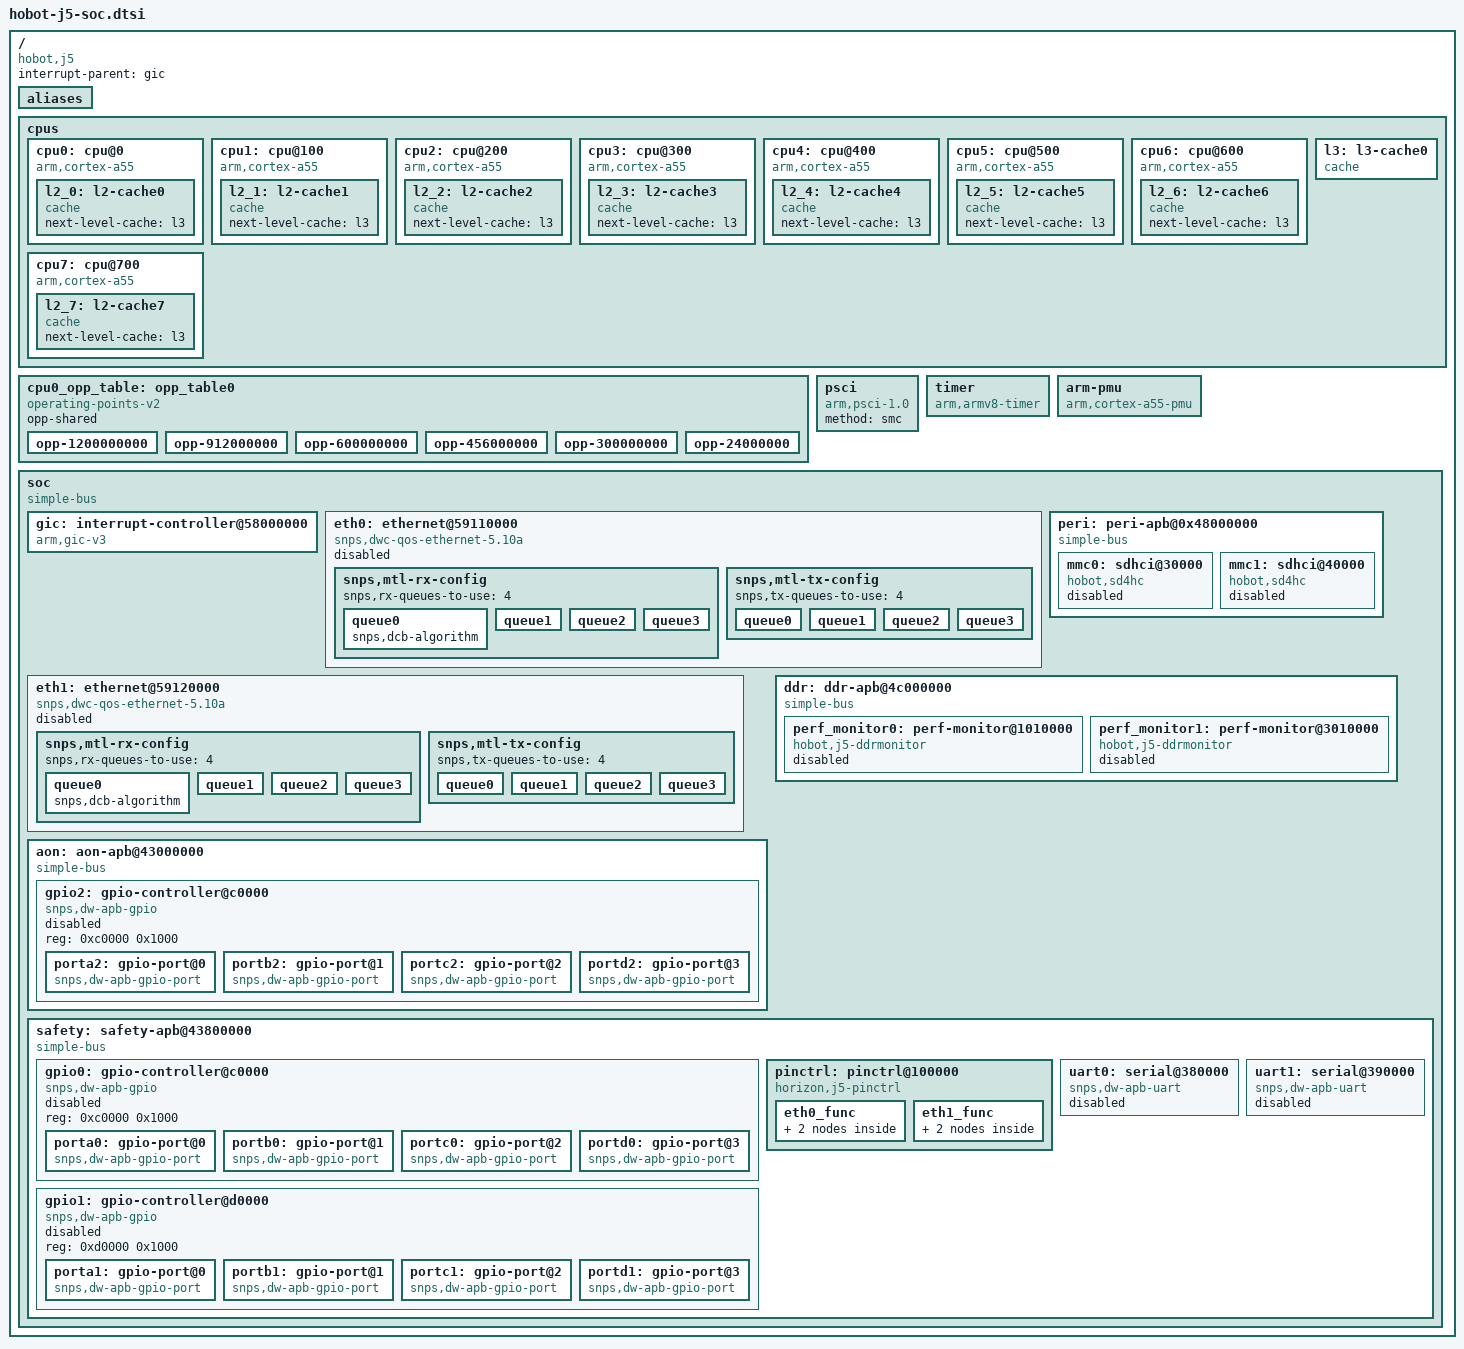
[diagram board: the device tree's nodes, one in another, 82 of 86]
// SPDX-License-Identifier: (GPL-2.0+ OR MIT)
/*
 * Copyright (c) 2021 Beijing Horizon Robotics Co., Ltd
 */

#include <dt-bindings/interrupt-controller/arm-gic.h>
#include <dt-bindings/interrupt-controller/irq.h>
/ {
	compatible = "hobot,j5";

	interrupt-parent = <&gic>;
	#address-cells = <2>;
	#size-cells = <2>;

	aliases {
		serial0 = &uart0;
		serial1 = &uart1;
		mmc0 = &mmc0;
		mmc1 = &mmc1;
	};

	cpus {
		#address-cells = <2>;
		#size-cells = <0>;

		cpu0: cpu@0 {
			device_type = "cpu";
			compatible = "arm,cortex-a55";
			reg = <0x0 0x0>;
			enable-method = "psci";
			next-level-cache = <&l2_0>;
			operating-points-v2 = <&cpu0_opp_table>;

			l2_0: l2-cache0 {
				compatible = "cache";
				next-level-cache = <&l3>;
			};
		};

		cpu1: cpu@100 {
			device_type = "cpu";
			compatible = "arm,cortex-a55";
			reg = <0x0 0x100>;
			enable-method = "psci";
			next-level-cache = <&l2_1>;
			operating-points-v2 = <&cpu0_opp_table>;

			l2_1: l2-cache1 {
				compatible = "cache";
				next-level-cache = <&l3>;
			};
		};

		cpu2: cpu@200 {
			device_type = "cpu";
			compatible = "arm,cortex-a55";
			reg = <0x0 0x200>;
			enable-method = "psci";
			next-level-cache = <&l2_2>;
			operating-points-v2 = <&cpu0_opp_table>;

			l2_2: l2-cache2 {
				compatible = "cache";
				next-level-cache = <&l3>;
			};
		};

		cpu3: cpu@300 {
			device_type = "cpu";
			compatible = "arm,cortex-a55";
			reg = <0x0 0x300>;
			enable-method = "psci";
			next-level-cache = <&l2_3>;
			operating-points-v2 = <&cpu0_opp_table>;

			l2_3: l2-cache3 {
				compatible = "cache";
				next-level-cache = <&l3>;
			};
		};

		cpu4: cpu@400 {
			device_type = "cpu";
			compatible = "arm,cortex-a55";
			reg = <0x0 0x400>;
			enable-method = "psci";
			next-level-cache = <&l2_4>;
			operating-points-v2 = <&cpu0_opp_table>;

			l2_4: l2-cache4 {
				compatible = "cache";
				next-level-cache = <&l3>;
			};
		};

		cpu5: cpu@500 {
			device_type = "cpu";
			compatible = "arm,cortex-a55";
			reg = <0x0 0x500>;
			enable-method = "psci";
			next-level-cache = <&l2_5>;
			operating-points-v2 = <&cpu0_opp_table>;

			l2_5: l2-cache5 {
				compatible = "cache";
				next-level-cache = <&l3>;
			};
		};

		cpu6: cpu@600 {
			device_type = "cpu";
			compatible = "arm,cortex-a55";
			reg = <0x0 0x600>;
			enable-method = "psci";
			next-level-cache = <&l2_6>;
			operating-points-v2 = <&cpu0_opp_table>;

			l2_6: l2-cache6 {
				compatible = "cache";
				next-level-cache = <&l3>;
			};
		};

		cpu7: cpu@700 {
			device_type = "cpu";
			compatible = "arm,cortex-a55";
			reg = <0x0 0x700>;
			enable-method = "psci";
			next-level-cache = <&l2_7>;
			operating-points-v2 = <&cpu0_opp_table>;

			l2_7: l2-cache7 {
				compatible = "cache";
				next-level-cache = <&l3>;
			};
		};

		l3: l3-cache0 {
			compatible = "cache";
		};
	};

	cpu0_opp_table: opp_table0 {
		compatible = "operating-points-v2";
		opp-shared;

		opp-1200000000 {
			opp-hz = /bits/ 64 <1200000000>;
			opp-microvolt = <800000>;
			clock-latency-ns = <500000>;
		};
		opp-912000000 {
			opp-hz = /bits/ 64 <912000000>;
			opp-microvolt = <800000>;
			clock-latency-ns = <500000>;
		};
		opp-600000000 {
			opp-hz = /bits/ 64 <600000000>;
			opp-microvolt = <800000>;
			clock-latency-ns = <500000>;
		};
		opp-456000000 {
			opp-hz = /bits/ 64 <456000000>;
			opp-microvolt = <800000>;
			clock-latency-ns = <500000>;
		};
		opp-300000000 {
			opp-hz = /bits/ 64 <300000000>;
			opp-microvolt = <800000>;
			clock-latency-ns = <500000>;
		};
		opp-24000000 {
			opp-hz = /bits/ 64 <24000000>;
			opp-microvolt = <800000>;
			clock-latency-ns = <500000>;
		};
	};

	psci {
		compatible = "arm,psci-1.0", "arm,psci-0.2";
		method = "smc";
	};

	timer {
		compatible = "arm,armv8-timer";
		clock-frequency = <24000000>;
		interrupts = <GIC_PPI 13 (GIC_CPU_MASK_SIMPLE(4) | IRQ_TYPE_LEVEL_LOW)>,
				<GIC_PPI 14 (GIC_CPU_MASK_SIMPLE(4) | IRQ_TYPE_LEVEL_LOW)>,
				<GIC_PPI 11 (GIC_CPU_MASK_SIMPLE(4) | IRQ_TYPE_LEVEL_LOW)>,
				<GIC_PPI 10 (GIC_CPU_MASK_SIMPLE(4) | IRQ_TYPE_LEVEL_LOW)>;
	};

	arm-pmu {
		compatible = "arm,cortex-a55-pmu", "arm,armv8-pmuv3";
		interrupts = <GIC_PPI 7 4>;
		interrupt-affinity = <&cpu0>, <&cpu1>, <&cpu2>, <&cpu3>,
				<&cpu4>, <&cpu5>, <&cpu6>, <&cpu7>;
	};

	soc {
		compatible = "simple-bus";
		#address-cells = <2>;
		#size-cells = <2>;
		ranges;

		gic: interrupt-controller@58000000 {
			compatible = "arm,gic-v3";
			#interrupt-cells = <3>;
			#address-cells = <2>;
			#size-cells = <2>;
			interrupt-controller;
			reg = <0x0 0x58000000 0x0 0x10000>,
				<0x0 0x58040000 0x0 0x100000>;
			interrupts = <GIC_PPI 9 IRQ_TYPE_LEVEL_HIGH>;
		};

		eth0: ethernet@59110000 {
			compatible = "snps,dwc-qos-ethernet-5.10a";
			reg = <0 0x59110000 0 0x2000>;
			interrupts = <GIC_SPI 8 IRQ_TYPE_LEVEL_HIGH>,
					<GIC_SPI 9 IRQ_TYPE_LEVEL_HIGH>;
			pinctrl-names = "eth_state";
			pinctrl-0 = <&eth0_func>;
			status = "disabled";
			snps,write-requests = <8>;
			snps,read-requests = <8>;
			snps,txpbl = <4>;
			snps,rxpbl = <4>;
			snps,clk_csr = <2>;
			snps,tso = <1>;
			snps,aal = <1>;
			snps,force_sf_dma_mode = <1>;
			module_index = <0>;
			snps,mtl-rx-config {
				snps,rx-queues-to-use = <4>;
				queue0 {
					snps,dcb-algorithm;
				};
				 queue1 {
					snps,avb-algorithm;
					snps,route-ptp;
				 };
				 queue2 {
					snps,priority = <0x4>;
					snps,avb-algorithm;
				 };
				 queue3 {
					snps,avb-algorithm;
					snps,priority = <0x8>;
				 };
			};
			snps,mtl-tx-config {
				snps,tx-queues-to-use = <4>;
				queue0 {
					snps,dcb-algorithm;
					snps,tx-sched-sp;
				};
				queue1 {
					snps,avb-algorithm;
					snps,idle_slope = <0x38e>;
					snps,send_slope = <0x1ccc>;
					snps,high_credit = <0x556aaa>;
					snps,low_credit = <0xff57400>;
					snps,priority = <0x2>;
				};
				queue2 {
					snps,avb-algorithm;
					snps,idle_slope = <0x8e4>;
					snps,send_slope = <0x1800>;
					snps,high_credit = <0x7d0000>;
					snps,low_credit = <0xff736000>;
					snps,priority = <0x4>;
				};
				queue3 {
					snps,avb-algorithm;
					snps,idle_slope = <0xe38>;
					snps,send_slope = <0x1333>;
					snps,high_credit = <0x4b0000>;
					snps,low_credit = <0xff8f8000>;
					snps,priority = <0x8>;
				};
			};
		};

		eth1: ethernet@59120000 {
			compatible = "snps,dwc-qos-ethernet-5.10a";
			reg = <0 0x59120000 0 0x2000>;
			interrupts = <GIC_SPI 92 IRQ_TYPE_LEVEL_HIGH>,
					<GIC_SPI 93 IRQ_TYPE_LEVEL_HIGH>;
			pinctrl-names = "eth_state";
			pinctrl-0 = <&eth1_func>;
			status = "disabled";
			snps,write-requests = <8>;
			snps,read-requests = <8>;
			snps,txpbl = <4>;
			snps,rxpbl = <4>;
			snps,clk_csr = <2>;
			snps,tso = <1>;
			snps,aal = <1>;
			snps,force_sf_dma_mode = <1>;
			module_index = <1>;
			snps,mtl-rx-config {
				snps,rx-queues-to-use = <4>;
				queue0 {
					snps,dcb-algorithm;
				};
				queue1 {
					snps,avb-algorithm;
					snps,route-ptp;
				};
				queue2 {
					snps,priority = <0x4>;
					snps,avb-algorithm;
				};
				queue3 {
					snps,avb-algorithm;
					snps,priority = <0x8>;
				};
			};
			snps,mtl-tx-config {
				snps,tx-queues-to-use = <4>;
				queue0 {
					snps,dcb-algorithm;
					snps,tx-sched-sp;
				};
				queue1 {
					snps,avb-algorithm;
					snps,idle_slope = <0x38e>;
					snps,send_slope = <0x1ccc>;
					snps,high_credit = <0x556aaa>;
					snps,low_credit = <0xff57400>;
					snps,priority = <0x2>;
				};
				queue2 {
					snps,avb-algorithm;
					snps,idle_slope = <0x8e4>;
					snps,send_slope = <0x1800>;
					snps,high_credit = <0x7d0000>;
					snps,low_credit = <0xff736000>;
					snps,priority = <0x4>;
				};
				queue3 {
					snps,avb-algorithm;
					snps,idle_slope = <0xe38>;
					snps,send_slope = <0x1333>;
					snps,high_credit = <0x4b0000>;
					snps,low_credit = <0xff8f8000>;
					snps,priority = <0x8>;
				};
			};
		};

		aon: aon-apb@43000000 {
			compatible = "simple-bus";
			#address-cells = <1>;
			#size-cells = <1>;
			ranges = <0 0 0x43000000 0xd0000>;

			gpio2: gpio-controller@c0000 {
				compatible = "snps,dw-apb-gpio";
				reg = <0xc0000 0x1000>;
				#address-cells = <1>;
				#size-cells = <0>;
				status = "disabled";

				porta2: gpio-port@0 {
					compatible = "snps,dw-apb-gpio-port";
					gpio-controller;
					#gpio-cells = <2>;
					snps,nr-gpios = <32>;
					reg = <0>;
					interrupt-controller;
					#interrupt-cells = <2>;
					interrupts = <GIC_SPI 48 IRQ_TYPE_LEVEL_HIGH>;
				};

				portb2: gpio-port@1 {
					compatible = "snps,dw-apb-gpio-port";
					gpio-controller;
					#gpio-cells = <2>;
					snps,nr-gpios = <32>;
					reg = <1>;
				};

				portc2: gpio-port@2 {
					compatible = "snps,dw-apb-gpio-port";
					gpio-controller;
					#gpio-cells = <2>;
					snps,nr-gpios = <32>;
					reg = <2>;
				};

				portd2: gpio-port@3 {
					compatible = "snps,dw-apb-gpio-port";
					gpio-controller;
					#gpio-cells = <2>;
					snps,nr-gpios = <32>;
					reg = <3>;
				};
			};
		};

		peri: peri-apb@0x48000000 {
			compatible = "simple-bus";
			#address-cells = <1>;
			#size-cells = <1>;
			ranges = <0 0 0x48000000 0x220000>;

			mmc0: sdhci@30000 {
				compatible = "hobot,sd4hc";
				reg = <0x30000 0x10000>;
				interrupts = <GIC_SPI 88 IRQ_TYPE_LEVEL_HIGH>;
				sdhci-caps-mask = <0xffffffff 0xffffffff>;
				sdhci-caps = <0x00000070 0x546ec800>;
				max-frequency = <200000000>;
				bus-width = <8>;
				cap-mmc-highspeed;
				mmc-hs200-1_8v;
				no-sdio;
				no-sd;
				non-removable;
				cdns,phy-input-delay-sd-default = <8>;
				cdns,phy-input-delay-mmc-highspeed = <3>;
				cdns,phy-input-delay-mmc-ddr = <3>;
				cdns,phy-dll-delay-strobe = <33>; /* for hs400 */
				cdns,phy-dll-delay-sdclk = <45>;
				cdns,phy-dll-delay-sdclk-hsmmc = <45>; /* golden for hs400 */
				status = "disabled";
			};

			mmc1: sdhci@40000 {
				compatible = "hobot,sd4hc";
				reg = <0x40000 0x10000>;
				interrupts = <GIC_SPI 90 IRQ_TYPE_LEVEL_HIGH>;
				sdhci-caps-mask = <0xffffffff 0xffffffff>;
				sdhci-caps = <0x00000070 0x156ac800>;
				max-frequency = <200000000>;
				bus-width = <4>;
				cap-sd-highspeed;
				sd-uhs-sdr104;
				no-mmc;
				cdns,phy-input-delay-sd-default = <1>;
				cdns,phy-input-delay-sd-highspeed = <1>;
				cdns,phy-input-delay-sd-uhs-sdr12 = <1>;
				cdns,phy-input-delay-sd-uhs-sdr25 = <1>;
				cdns,phy-input-delay-sd-uhs-sdr50 = <1>;
				cdns,phy-input-delay-sd-uhs-ddr50 = <1>;
				cdns,phy-dll-delay-sdclk = <33>;
				cdns,phy-dll-delay-sdclk-hsmmc = <33>;
				status = "disabled";
			};
		};

		ddr: ddr-apb@4c000000 {
			compatible = "simple-bus";
			#address-cells = <1>;
			#size-cells = <1>;
			ranges = <0 0 0x4c000000 0x4000000>;

			perf_monitor0: perf-monitor@1010000 {
				compatible = "hobot,j5-ddrmonitor";
				reg = <0x1010000 0x1000>;
				interrupts = <GIC_SPI 141 IRQ_TYPE_LEVEL_HIGH>;
				core-index = <0>;
				status = "disabled";
			};

			perf_monitor1: perf-monitor@3010000 {
				compatible = "hobot,j5-ddrmonitor";
				reg = <0x3010000 0x1000>;
				interrupts = <GIC_SPI 158 IRQ_TYPE_LEVEL_HIGH>;
				core-index = <1>;
				status = "disabled";
			};
		};

		safety: safety-apb@43800000 {
			compatible = "simple-bus";
			#address-cells = <1>;
			#size-cells = <1>;
			ranges = <0 0 0x43800000 0x400000>;

			gpio0: gpio-controller@c0000 {
				compatible = "snps,dw-apb-gpio";
				reg = <0xc0000 0x1000>;
				#address-cells = <1>;
				#size-cells = <0>;
				status = "disabled";

				porta0: gpio-port@0 {
					compatible = "snps,dw-apb-gpio-port";
					gpio-controller;
					#gpio-cells = <2>;
					snps,nr-gpios = <32>;
					reg = <0>;
					interrupt-controller;
					#interrupt-cells = <2>;
					interrupts = <GIC_SPI 46 IRQ_TYPE_LEVEL_HIGH>;
				};

				portb0: gpio-port@1 {
					compatible = "snps,dw-apb-gpio-port";
					gpio-controller;
					#gpio-cells = <2>;
					snps,nr-gpios = <32>;
					reg = <1>;
				};

				portc0: gpio-port@2 {
					compatible = "snps,dw-apb-gpio-port";
					gpio-controller;
					#gpio-cells = <2>;
					snps,nr-gpios = <32>;
					reg = <2>;
				};

				portd0: gpio-port@3 {
					compatible = "snps,dw-apb-gpio-port";
					gpio-controller;
					#gpio-cells = <2>;
					snps,nr-gpios = <32>;
					reg = <3>;
				};
			};

			gpio1: gpio-controller@d0000 {
				compatible = "snps,dw-apb-gpio";
				reg = <0xd0000 0x1000>;
				#address-cells = <1>;
				#size-cells = <0>;
				status = "disabled";

				porta1: gpio-port@0 {
					compatible = "snps,dw-apb-gpio-port";
					gpio-controller;
					#gpio-cells = <2>;
					snps,nr-gpios = <32>;
					reg = <0>;
					interrupt-controller;
					#interrupt-cells = <2>;
					interrupts = <GIC_SPI 47 IRQ_TYPE_LEVEL_HIGH>;
				};

				portb1: gpio-port@1 {
					compatible = "snps,dw-apb-gpio-port";
					gpio-controller;
					#gpio-cells = <2>;
					snps,nr-gpios = <32>;
					reg = <1>;
				};

				portc1: gpio-port@2 {
					compatible = "snps,dw-apb-gpio-port";
					gpio-controller;
					#gpio-cells = <2>;
					snps,nr-gpios = <32>;
					reg = <2>;
				};

				portd1: gpio-port@3 {
					compatible = "snps,dw-apb-gpio-port";
					gpio-controller;
					#gpio-cells = <2>;
					snps,nr-gpios = <32>;
					reg = <3>;
				};
			};

			pinctrl: pinctrl@100000 {
				compatible = "horizon,j5-pinctrl";
				reg = <0x100000 0x1000>,
					<0x110000 0x1000>,
					<0x120000 0x1000>,
					<0x130000 0x1000>,
					<0x140000 0x1000>;

				eth0_func: eth0_func {
					pinmux {
						function = "emac0";
						pins = "emac0_phy_int","emac0_phy_ref_clk","emac0_crs","emac0_col",
							"emac0_mdc","emac0_mdio","emac0_tx_clk","emac0_tx_en",
							"emac0_tx_er","emac0_tx_d7","emac0_tx_d6","emac0_tx_d5",
							"emac0_tx_d4","emac0_tx_d3","emac0_tx_d2","emac0_tx_d1",
							"emac0_tx_d0","emac0_rx_clk","emac0_rx_dv","emac0_rx_er",
							"emac0_rx_d7","emac0_rx_d6","emac0_rx_d5","emac0_rx_d4",
							"emac0_rx_d3","emac0_rx_d2","emac0_rx_d1","emac0_rx_d0";
					};

					pinconf {
						pins = "emac0_phy_int","emac0_phy_ref_clk","emac0_crs","emac0_col",
							"emac0_mdc","emac0_mdio","emac0_tx_clk","emac0_tx_en",
							"emac0_tx_er","emac0_tx_d7","emac0_tx_d6","emac0_tx_d5",
							"emac0_tx_d4","emac0_tx_d3","emac0_tx_d2","emac0_tx_d1",
							"emac0_tx_d0","emac0_rx_clk","emac0_rx_dv","emac0_rx_er",
							"emac0_rx_d7","emac0_rx_d6","emac0_rx_d5","emac0_rx_d4",
							"emac0_rx_d3","emac0_rx_d2","emac0_rx_d1","emac0_rx_d0";
					};
				};

				eth1_func: eth1_func {
					pinmux {
						function = "emac1";
						pins = "emac1_phy_int","emac1_phy_ref_clk","emac1_crs","emac1_col",
							"emac1_mdc","emac1_mdio","emac1_tx_clk","emac1_tx_en",
							"emac1_tx_er","emac1_tx_d3","emac1_tx_d2","emac1_tx_d1",
							"emac1_tx_d0","emac1_rx_clk","emac1_rx_dv","emac1_rx_er",
							"emac1_rx_d3","emac1_rx_d2","emac1_rx_d1","emac1_rx_d0";
					};

					pinconf {
						pins = "emac1_phy_int","emac1_phy_ref_clk","emac1_crs","emac1_col",
							"emac1_mdc","emac1_mdio","emac1_tx_clk","emac1_tx_en",
							"emac1_tx_er","emac1_tx_d3","emac1_tx_d2","emac1_tx_d1",
							"emac1_tx_d0","emac1_rx_clk","emac1_rx_dv","emac1_rx_er",
							"emac1_rx_d3","emac1_rx_d2","emac1_rx_d1","emac1_rx_d0";
					};
				};
			};

			uart0: serial@380000 {
				compatible = "snps,dw-apb-uart";
				reg = <0x380000 0x1000>;
				interrupts = <GIC_SPI 41 IRQ_TYPE_LEVEL_HIGH>;
				clock-frequency = <192000000>; //192MHz
				reg-io-width = <4>;
				reg-shift = <2>;
				status = "disabled";
			};

			uart1: serial@390000 {
				compatible = "snps,dw-apb-uart";
				reg = <0x390000 0x1000>;
				interrupts = <GIC_SPI 42 IRQ_TYPE_LEVEL_HIGH>;
				clock-frequency = <192000000>; //192MHz
				reg-io-width = <4>;
				reg-shift = <2>;
				status = "disabled";
			};
		};
	};
};
